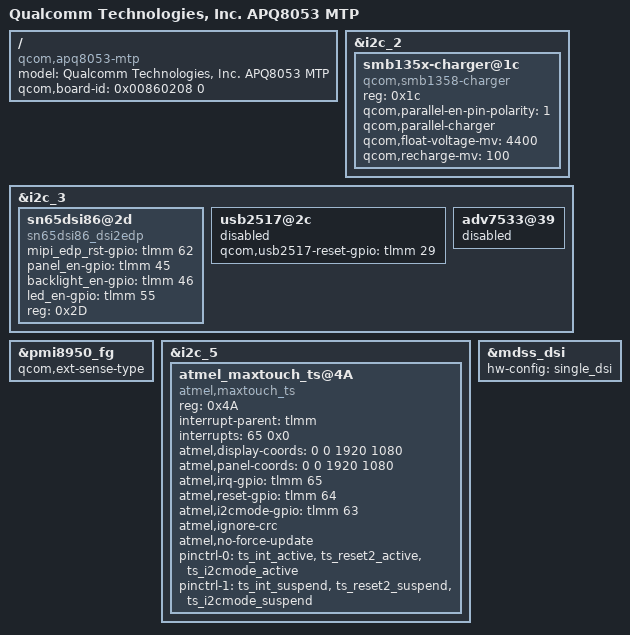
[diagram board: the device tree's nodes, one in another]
/*
 * Copyright (c) 2015-2016, The Linux Foundation. All rights reserved.
 *
 * This program is free software; you can redistribute it and/or modify
 * it under the terms of the GNU General Public License version 2 and
 * only version 2 as published by the Free Software Foundation.
 *
 * This program is distributed in the hope that it will be useful,
 * but WITHOUT ANY WARRANTY; without even the implied warranty of
 * MERCHANTABILITY or FITNESS FOR A PARTICULAR PURPOSE.  See the
 * GNU General Public License for more details.
 */

/dts-v1/;

#include "apq8053.dtsi"
#include "msm8953-mtp.dtsi"
#include "apq8053-oem.dtsi"
#include "apq8053-mtp-edp-hdmi.dtsi"//Leo Guo add to support all panel in one image
#include "apq8053-mtp-aaio2.dtsi"

/ {
	model = "Qualcomm Technologies, Inc. APQ8053 MTP";
	compatible = "qcom,apq8053-mtp", "qcom,apq8053", "qcom,mtp";
	qcom,board-id= <0x00860208 0>;
};

&i2c_2 {
	/* Parallel-charger configuration */
	smb135x-charger@1c {
		compatible = "qcom,smb1358-charger";
		reg = <0x1c>;
		qcom,parallel-en-pin-polarity = <1>;
		qcom,parallel-charger;
		qcom,float-voltage-mv = <4400>;
		qcom,recharge-mv = <100>;
	};
};

&i2c_3 {
	sn65dsi86@2d {
		compatible = "sn65dsi86_dsi2edp";
		mipi_edp_rst-gpio =<&tlmm 62 0>;
		panel_en-gpio = <&tlmm 45 0>;
		backlight_en-gpio = <&tlmm 46 0>;
		led_en-gpio = <&tlmm 55 0>;
		reg = <0x2D>;
	};

	/*JackWLu: Add reset PIN for 10.1 I2.0 EVT2*/
	usb2517@2c {
		qcom,usb2517-reset-gpio = <&tlmm 29 0>; /*for HUB2.0 usb2517 reset pin*/
		status = "disabled";/*Value not use this setting*/
	};
};

&pmi8950_fg {
	/* use external rsense for parallel charging */
	qcom,ext-sense-type;
};

/*oem,tony.l.cai,20170718,porting for atmel touch{*/
&i2c_5 {
	/* Atmel touch configuration */
	atmel_maxtouch_ts@4A {
		compatible = "atmel,maxtouch_ts";
		reg = <0x4A>;
		interrupt-parent = <&tlmm>;
		interrupts = <65 0x0>;
		atmel,display-coords = <0 0 1920 1080>;
		atmel,panel-coords = <0 0 1920 1080>;
		atmel,irq-gpio= <&tlmm 65 0x00>;
		atmel,reset-gpio= <&tlmm 64 0x00>;
		atmel,i2cmode-gpio = <&tlmm 63 0>;
		atmel,ignore-crc;
		atmel,no-force-update;
		pinctrl-names = "pmx_ts_active","pmx_ts_suspend","pmx_ts_i2cmode_active";
		pinctrl-0 = <&ts_int_active &ts_reset2_active &ts_i2cmode_active>;
		pinctrl-1 = <&ts_int_suspend &ts_reset2_suspend &ts_i2cmode_suspend>;
	};
};
/*}oem,tony.l.cai,20170718,porting for atmel touch*/
/*20170920,Leo Guo add to disable HDMI for I20 value*/
&i2c_3 {
	adv7533@39 {
		status="disabled";
	};
};

&mdss_dsi {
	hw-config = "single_dsi";
};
